VERSION ""

NS_ :

BS_:

BU_: XXX EPS

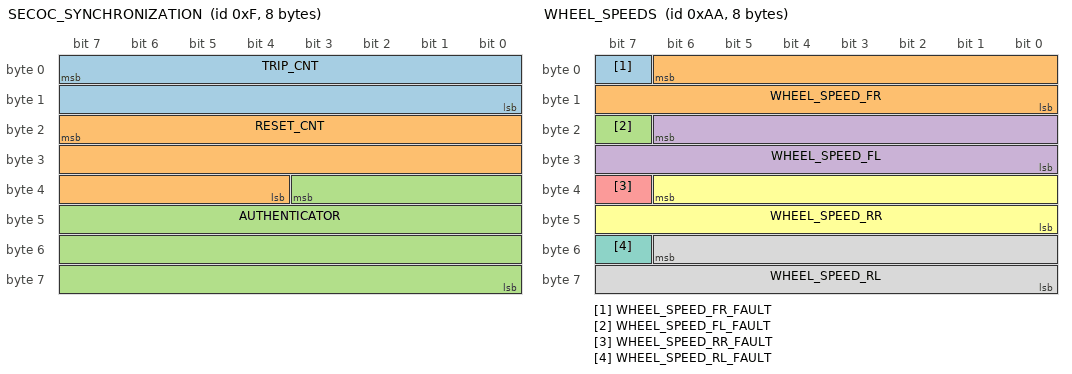
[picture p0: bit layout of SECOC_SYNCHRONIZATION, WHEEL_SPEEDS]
BO_ 15 SECOC_SYNCHRONIZATION: 8 XXX
 SG_ TRIP_CNT : 7|16@0+ (1,0) [0|65535] "" XXX
 SG_ RESET_CNT : 23|20@0+ (1,0) [0|1048575] "" XXX
 SG_ AUTHENTICATOR : 35|28@0+ (1,0) [0|268435455] "" XXX

BO_ 37 STEER_ANGLE_SENSOR: 32 XXX
 SG_ STEER_ANGLE : 3|12@0- (1.5,0) [-500|500] "deg" XXX
 SG_ STEER_FRACTION : 39|4@0- (0.1,0) [-0.7|0.7] "deg" XXX
 SG_ STEER_RATE : 35|12@0- (1,0) [-2000|2000] "deg/s" XXX

BO_ 48 TSS3_EPS_TELEMETRY: 32 EPS
 SG_ STEERING_WHEEL_TORQUE_TRUNC : 7|8@0- (0.1,0) [-12.8|12.7] "Nm" XXX
 SG_ EPS_STATUS_B6_BIT3 : 51|1@0+ (1,0) [0|1] "" XXX
 SG_ STEERING_FAULT_INHIBIT_STATUS : 50|1@0+ (1,0) [0|1] "" XXX
 SG_ EPS_STATUS_B6_BIT1 : 49|1@0+ (1,0) [0|1] "" XXX
 SG_ DRIVER_TORQUE_INVALID : 48|1@0+ (1,0) [0|1] "" XXX
 SG_ ADDITIVE_BYTE_7 : 63|8@0+ (1,0) [0|255] "" XXX
 SG_ STEERING_WHEEL_TORQUE_COARSE : 71|8@0- (0.1,0) [-12.8|12.7] "Nm" XXX
 SG_ STEERING_WHEEL_TORQUE_FINE : 139|4@0- (0.01,0) [-0.08|0.07] "Nm" XXX

BO_ 170 WHEEL_SPEEDS: 8 XXX
 SG_ WHEEL_SPEED_FR_FAULT : 7|1@0+ (1,0) [0|1] "" XXX
 SG_ WHEEL_SPEED_FR : 6|15@0+ (0.01,-67.67) [-67.67|260] "km/h" XXX
 SG_ WHEEL_SPEED_FL_FAULT : 23|1@0+ (1,0) [0|1] "" XXX
 SG_ WHEEL_SPEED_FL : 22|15@0+ (0.01,-67.67) [-67.67|260] "km/h" XXX
 SG_ WHEEL_SPEED_RR_FAULT : 39|1@0+ (1,0) [0|1] "" XXX
 SG_ WHEEL_SPEED_RR : 38|15@0+ (0.01,-67.67) [-67.67|260] "km/h" XXX
 SG_ WHEEL_SPEED_RL_FAULT : 55|1@0+ (1,0) [0|1] "" XXX
 SG_ WHEEL_SPEED_RL : 54|15@0+ (0.01,-67.67) [-67.67|260] "km/h" XXX

BO_ 182 TSS3_LATERAL_CONTROL: 32 XXX
 SG_ TARGET_LATERAL_ID : 29|6@0+ (1,0) [0|63] "" XXX
 SG_ TARGET_STEERING_ANGLE : 39|16@0- (0.057302742,0) [-1877|1877] "deg" XXX
 SG_ SEQUENCE : 61|6@0+ (1,0) [0|63] "" XXX

BO_ 257 BRAKE_MODULE: 8 XXX
 SG_ BRAKE_PRESSED : 3|1@0+ (1,0) [0|1] "" XXX
 SG_ CHECKSUM : 63|8@0+ (1,0) [0|255] "" XXX

BO_ 278 GAS_PEDAL: 8 XXX
 SG_ GAS_PEDAL_USER : 15|8@0+ (0.005,0) [0|1.275] "" XXX

BO_ 295 GEAR_PACKET_HYBRID: 8 XXX
 SG_ GEAR : 47|4@0+ (1,0) [0|15] "" XXX
 SG_ CHECKSUM : 63|8@0+ (1,0) [0|255] "" XXX

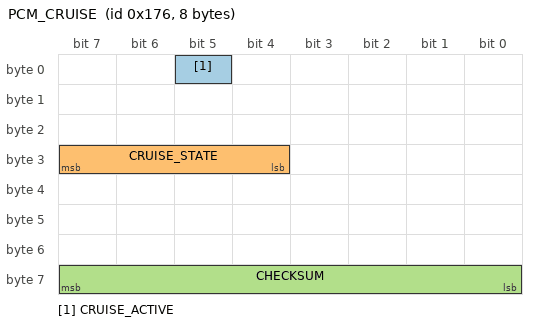
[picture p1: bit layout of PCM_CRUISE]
BO_ 374 PCM_CRUISE: 8 XXX
 SG_ CRUISE_ACTIVE : 5|1@0+ (1,0) [0|1] "" XXX
 SG_ CRUISE_STATE : 31|4@0+ (1,0) [0|15] "" XXX
 SG_ CHECKSUM : 63|8@0+ (1,0) [0|255] "" XXX

BO_ 1310 TSS3_READY_STATUS: 8 XXX
 SG_ READY_STATUS : 7|1@0+ (1,0) [0|1] "" XXX

BO_ 1556 BLINKERS_STATE: 8 XXX
 SG_ TURN_SIGNALS : 29|2@0+ (1,0) [0|3] "" XXX

BO_ 1568 BODY_CONTROL_STATE: 8 XXX
 SG_ PARKING_BRAKE : 60|1@0+ (1,0) [0|1] "" XXX

CM_ BO_ 37 "TSS3 Corolla uses the legacy steering angle/fraction/rate bit positions inside a 32-byte CAN-FD PDU; exact H firmware and two driving captures support these fields.";
CM_ BO_ 48 "Exact H/F EPS transmits this 32-byte PDU. Driver torque and B6 safety/status gates are target-native recovered fields; byte 7 equals sum(bytes 0..6)+0x38 modulo 256.";
CM_ SG_ 48 STEERING_WHEEL_TORQUE_TRUNC "DID 0x1035 Steering Wheel Torque source, saturating truncation-toward-zero 0.1 Nm view. It can differ from COARSE by one count due to firmware rounding.";
CM_ SG_ 48 STEERING_WHEEL_TORQUE_COARSE "Coarse component of exact physical Steering Wheel Torque reconstruction.";
CM_ SG_ 48 STEERING_WHEEL_TORQUE_FINE "Signed hundredths remainder. Exact torque = COARSE + FINE; Span exercises -0.05..+0.05 Nm remainder.";
CM_ SG_ 48 STEERING_FAULT_INHIBIT_STATUS "Target-native selected steering fault/inhibit status aggregate from FEBE7DAE; nominal-clear in all 6000 tracked Span frames. This is not an exhaustive EPS-fault bitmap. Do not infer temporary/permanent openpilot fault class.";
CM_ SG_ 48 DRIVER_TORQUE_INVALID "Target-native driver-torque invalid/inhibit gate from FEBE7DB2; nominal-clear in all 6000 tracked Span frames.";
CM_ SG_ 48 EPS_STATUS_B6_BIT1 "Runtime status bit from FEBE7DB3; exact OEM meaning unresolved.";
CM_ SG_ 48 EPS_STATUS_B6_BIT3 "Runtime status bit from FEBE7E09; exact OEM meaning unresolved.";
CM_ BO_ 182 "Exact H/F protected lateral receiver PDU. Receiver-side fields are defined for analysis only; transmission remains disabled.";
CM_ SG_ 182 TARGET_LATERAL_ID "Techstream Target Lateral ID; exact H accepts 1=PCS, 4=LDA, 10=Hands Off LTA, 11=LTA/LCA, 19=PDA. 0 means no request.";
CM_ SG_ 182 TARGET_STEERING_ANGLE "Controller-equivalent scale is exactly 1024/17870 deg/count (~0.057302742 deg/count). OEM wire-unit label remains unjoined.";
CM_ SG_ 182 SEQUENCE "Exact H receiver treats this as a modulo-64 sequence counter with effective gap cap 8.";
CM_ SG_ 295 GEAR "Only raw 3=D has been dynamically validated on the tracked TSS3 Corolla capture; remaining enum values are retained from Toyota prior art pending target transitions.";
CM_ SG_ 374 CRUISE_ACTIVE "Wire location/checksum are retained Toyota prior art and observed on moving TSS3 Corolla captures; an active cruise transition has not yet been captured.";
CM_ SG_ 1310 READY_STATUS "Exact H PDU29 signal154: incoming 0x51E B0[7] feeds DID 0x1033 Ready Status. Both retained operational captures show value 1 only; do not infer Ready=0 fault policy without a transition.";

VAL_ 182 TARGET_LATERAL_ID 27 "Remote Parking" 25 "AP" 19 "PDA" 11 "LTA/LCA" 10 "Hands Off LTA" 4 "LDA" 1 "PCS" 0 "No Request";
VAL_ 295 GEAR 4 "B" 3 "D" 2 "N" 1 "R" 0 "P";
VAL_ 1556 TURN_SIGNALS 3 "hazard" 2 "right" 1 "left" 0 "none";
